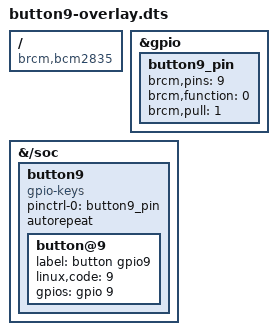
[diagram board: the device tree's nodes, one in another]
/dts-v1/;
/plugin/;

/ {
    compatible = "brcm,bcm2835", "brcm,bcm2708", "brcm,bcm2709";

    fragment@0 {
        target = <&gpio>;
        __overlay__ {
            button9_pin: button9_pin {
                brcm,pins = <9>;     /* gpio9 */
                brcm,function = <0>; /* input */
                brcm,pull = <1>;     /* pull-down */
            };
        };
    };

    fragment@1 {
    target-path = "/soc";
        __overlay__ {
            button9: button9 {
                compatible = "gpio-keys";
                #address-cells = <1>;
                #size-cells = <0>;
                pinctrl-names = "default";
                pinctrl-0 = <&button9_pin>;
                status = "okay";
                autorepeat;

                button@9 {
                    label = "button gpio9";
                    linux,code = <9>;
                    gpios = <&gpio 9 0>;
                };
            };
        };
    };
};

